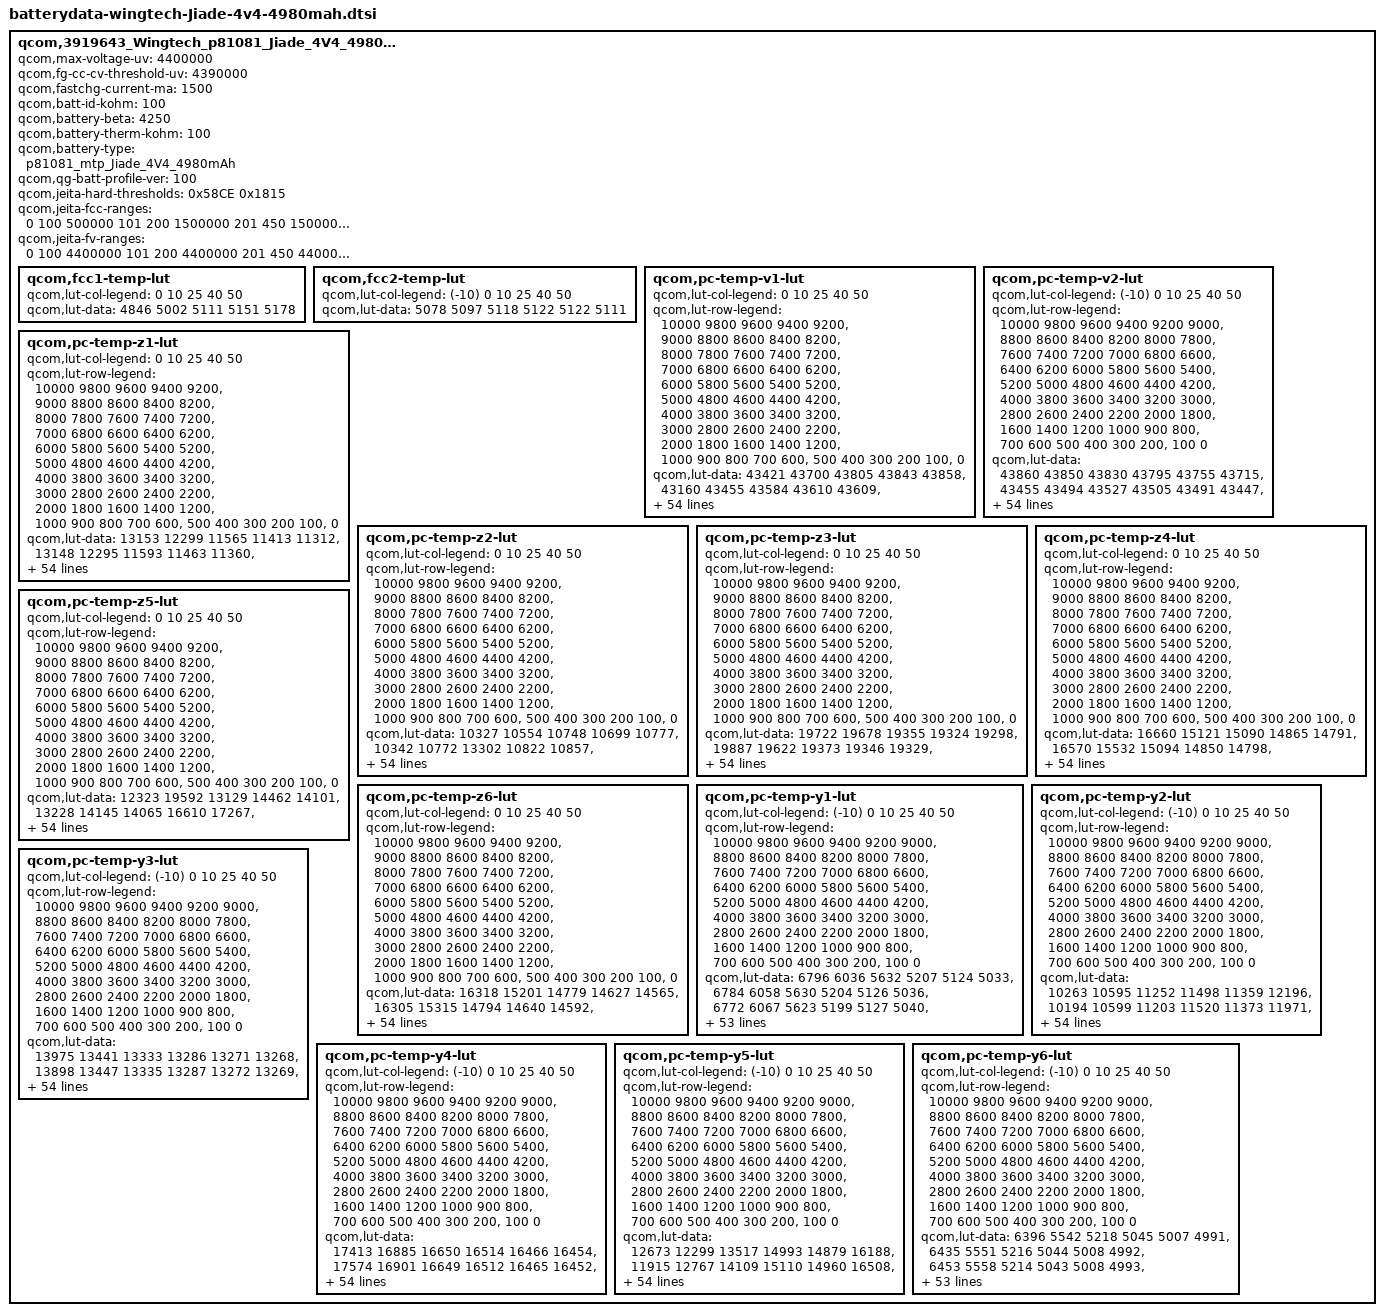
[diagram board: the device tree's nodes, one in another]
qcom,3919643_Wingtech_p81081_Jiade_4V4_4980mAh {
    /* 3919643_Wingtech_p81081_Jiade_4V4_4980mAh_averaged_MasterSlave_Mar12th2019 */
    qcom,max-voltage-uv = <4400000>;
    qcom,fg-cc-cv-threshold-uv = <4390000>;
    qcom,fastchg-current-ma = <1500>;
    qcom,batt-id-kohm = <100>;
    qcom,battery-beta = <4250>;
    qcom,battery-therm-kohm = <100>;
    qcom,battery-type = "p81081_mtp_Jiade_4V4_4980mAh";
    qcom,qg-batt-profile-ver = <100>;

	/*bug 432160 caijiaqi.wt 20190314 0-55 degree C charging, other temperatur don't charging*/
	/* COLD = 0 DegC, HOT = 55 DegC */
	qcom,jeita-hard-thresholds = <0x58CE 0x1815>;
	qcom,jeita-fcc-ranges = <0   100  500000
                                101  200  1500000
                                201  450  1500000
                                451  550  800000>;
        qcom,jeita-fv-ranges = <0   100  4400000
                                101 200  4400000
                                201 450  4400000
                                451 550  4100000>;
	/*bug 432160 caijiaqi.wt 20190314 0-55 degree C charging, other temperatur don't charging*/

	qcom,fcc1-temp-lut {
		qcom,lut-col-legend = <0 10 25 40 50>;
		qcom,lut-data = <4846 5002 5111 5151 5178>;
	};

	qcom,fcc2-temp-lut {
		qcom,lut-col-legend = <(-10) 0 10 25 40 50>;
		qcom,lut-data = <5078 5097 5118 5122 5122 5111>;
	};

	qcom,pc-temp-v1-lut {
		qcom,lut-col-legend = <0 10 25 40 50>;
		qcom,lut-row-legend = <10000 9800 9600 9400 9200>,
			<9000 8800 8600 8400 8200>,
			<8000 7800 7600 7400 7200>,
			<7000 6800 6600 6400 6200>,
			<6000 5800 5600 5400 5200>,
			<5000 4800 4600 4400 4200>,
			<4000 3800 3600 3400 3200>,
			<3000 2800 2600 2400 2200>,
			<2000 1800 1600 1400 1200>,
			<1000 900 800 700 600>,
			<500 400 300 200 100>,
			<0>;
		qcom,lut-data = <43421 43700 43805 43843 43858>,
			<43160 43455 43584 43610 43609>,
			<42917 43201 43344 43383 43387>,
			<42684 42955 43097 43156 43157>,
			<42456 42717 42853 42927 42924>,
			<42231 42484 42614 42691 42692>,
			<42009 42253 42379 42453 42459>,
			<41793 42026 42147 42217 42228>,
			<41580 41804 41919 41986 41998>,
			<41379 41585 41693 41757 41769>,
			<41201 41373 41469 41531 41542>,
			<41026 41181 41253 41311 41319>,
			<40816 41000 41053 41099 41101>,
			<40560 40797 40861 40898 40893>,
			<40320 40553 40654 40694 40688>,
			<40125 40319 40433 40484 40484>,
			<39954 40135 40228 40282 40287>,
			<39805 39975 40051 40103 40107>,
			<39679 39827 39888 39938 39939>,
			<39562 39696 39736 39777 39775>,
			<39444 39561 39598 39626 39618>,
			<39329 39404 39425 39457 39451>,
			<39213 39233 39158 39215 39234>,
			<39096 39050 38903 38959 38993>,
			<38980 38835 38759 38804 38822>,
			<38860 38661 38655 38700 38702>,
			<38738 38568 38570 38603 38595>,
			<38630 38502 38499 38500 38491>,
			<38536 38446 38433 38405 38395>,
			<38455 38400 38363 38321 38306>,
			<38398 38357 38297 38247 38226>,
			<38354 38313 38237 38179 38154>,
			<38316 38269 38184 38121 38091>,
			<38281 38229 38135 38066 38033>,
			<38249 38193 38093 38018 37982>,
			<38215 38156 38054 37973 37934>,
			<38184 38122 38013 37925 37877>,
			<38146 38085 37974 37875 37811>,
			<38087 38030 37921 37813 37736>,
			<38004 37935 37832 37728 37653>,
			<37905 37825 37721 37625 37559>,
			<37784 37710 37606 37513 37448>,
			<37645 37579 37477 37385 37316>,
			<37485 37417 37318 37229 37164>,
			<37341 37272 37172 37084 37021>,
			<37249 37174 37081 36996 36934>,
			<37224 37145 37060 36973 36913>,
			<37192 37127 37040 36960 36898>,
			<37168 37105 37023 36943 36878>,
			<37118 37063 36977 36884 36810>,
			<36875 36829 36730 36620 36534>,
			<36429 36391 36299 36186 36094>,
			<35854 35818 35729 35614 35524>,
			<35070 35035 34950 34832 34742>,
			<33843 33816 33743 33626 33536>,
			<30000 30000 30000 30000 30000>;
	};

	qcom,pc-temp-v2-lut {
		qcom,lut-col-legend = <(-10) 0 10 25 40 50>;
		qcom,lut-row-legend = <10000 9800 9600 9400 9200 9000>,
			<8800 8600 8400 8200 8000 7800>,
			<7600 7400 7200 7000 6800 6600>,
			<6400 6200 6000 5800 5600 5400>,
			<5200 5000 4800 4600 4400 4200>,
			<4000 3800 3600 3400 3200 3000>,
			<2800 2600 2400 2200 2000 1800>,
			<1600 1400 1200 1000 900 800>,
			<700 600 500 400 300 200>,
			<100 0>;
		qcom,lut-data = <43860 43850 43830 43795 43755 43715>,
			<43455 43494 43527 43505 43491 43447>,
			<43091 43172 43244 43233 43236 43189>,
			<42772 42887 42983 42979 42992 42943>,
			<42488 42636 42742 42744 42758 42709>,
			<42239 42393 42505 42511 42525 42477>,
			<42031 42153 42268 42276 42291 42244>,
			<41832 41918 42035 42044 42058 42012>,
			<41580 41684 41807 41815 41830 41784>,
			<41284 41451 41584 41589 41606 41559>,
			<41088 41238 41367 41366 41383 41337>,
			<41004 41057 41155 41146 41163 41120>,
			<40916 40877 40948 40931 40948 40907>,
			<40612 40673 40753 40730 40745 40705>,
			<40037 40449 40561 40535 40548 40507>,
			<39670 40198 40352 40335 40350 40315>,
			<39492 39892 40120 40125 40146 40126>,
			<39342 39616 39889 39930 39955 39944>,
			<39172 39434 39675 39772 39796 39779>,
			<39001 39285 39468 39621 39643 39617>,
			<38830 39122 39267 39427 39452 39426>,
			<38649 38949 39070 39182 39221 39199>,
			<38495 38787 38896 38965 39010 38991>,
			<38384 38642 38745 38790 38831 38814>,
			<38293 38507 38611 38639 38673 38659>,
			<38215 38373 38490 38515 38545 38532>,
			<38150 38238 38380 38409 38437 38425>,
			<38089 38131 38280 38313 38339 38328>,
			<38030 38051 38189 38224 38248 38237>,
			<37975 37986 38103 38141 38165 38154>,
			<37923 37934 38016 38062 38091 38079>,
			<37875 37891 37933 37987 38021 38009>,
			<37825 37849 37870 37920 37956 37944>,
			<37773 37809 37821 37859 37897 37887>,
			<37720 37769 37778 37803 37834 37823>,
			<37663 37724 37740 37749 37752 37727>,
			<37603 37676 37702 37694 37662 37609>,
			<37541 37623 37657 37631 37573 37506>,
			<37474 37565 37604 37556 37483 37414>,
			<37405 37498 37541 37479 37398 37328>,
			<37334 37414 37459 37401 37328 37254>,
			<37260 37313 37361 37312 37245 37173>,
			<37182 37200 37247 37198 37128 37057>,
			<37101 37080 37108 37068 37005 36926>,
			<37012 36951 36956 36923 36871 36801>,
			<36906 36849 36882 36881 36829 36772>,
			<36853 36802 36855 36862 36819 36760>,
			<36780 36753 36833 36838 36799 36742>,
			<36705 36693 36794 36806 36769 36707>,
			<36599 36596 36723 36719 36680 36596>,
			<36381 36396 36484 36436 36391 36279>,
			<36036 36001 36023 35950 35913 35782>,
			<35490 35426 35393 35301 35272 35137>,
			<34685 34614 34536 34405 34384 34232>,
			<33357 33283 33183 32985 33046 32943>,
			<29091 28256 28322 28393 28647 28845>;
	};

	qcom,pc-temp-z1-lut {
		qcom,lut-col-legend = <0 10 25 40 50>;
		qcom,lut-row-legend = <10000 9800 9600 9400 9200>,
			<9000 8800 8600 8400 8200>,
			<8000 7800 7600 7400 7200>,
			<7000 6800 6600 6400 6200>,
			<6000 5800 5600 5400 5200>,
			<5000 4800 4600 4400 4200>,
			<4000 3800 3600 3400 3200>,
			<3000 2800 2600 2400 2200>,
			<2000 1800 1600 1400 1200>,
			<1000 900 800 700 600>,
			<500 400 300 200 100>,
			<0>;
		qcom,lut-data = <13153 12299 11565 11413 11312>,
			<13148 12295 11593 11463 11360>,
			<13167 12314 11586 11470 11354>,
			<13198 12323 11580 11473 11359>,
			<13209 12319 11574 11476 11366>,
			<13180 12311 11570 11476 11367>,
			<13147 12308 11566 11474 11360>,
			<13149 12305 11561 11471 11357>,
			<13171 12305 11553 11466 11361>,
			<13189 12310 11551 11460 11364>,
			<13196 12311 11553 11455 11362>,
			<13200 12299 11554 11451 11358>,
			<13201 12276 11553 11451 11356>,
			<13206 12268 11551 11453 11351>,
			<13204 12267 11548 11455 11348>,
			<13181 12267 11546 11459 11354>,
			<13145 12269 11543 11463 11362>,
			<13125 12272 11541 11465 11363>,
			<13117 12273 11540 11467 11360>,
			<13114 12268 11543 11468 11359>,
			<13106 12264 11552 11463 11359>,
			<13089 12274 11557 11460 11360>,
			<13087 12294 11557 11466 11362>,
			<13106 12298 11556 11474 11366>,
			<13124 12284 11557 11474 11369>,
			<13124 12274 11562 11468 11376>,
			<13117 12282 11564 11465 11380>,
			<13114 12300 11566 11472 11376>,
			<13119 12306 11569 11481 11370>,
			<13127 12302 11575 11482 11370>,
			<13135 12299 11581 11481 11375>,
			<13151 12304 11582 11482 11377>,
			<13161 12313 11579 11486 11381>,
			<13159 12320 11577 11490 11385>,
			<13155 12326 11581 11495 11384>,
			<13151 12331 11590 11500 11383>,
			<13136 12342 11594 11503 11383>,
			<13125 12356 11597 11505 11385>,
			<13144 12358 11600 11505 11387>,
			<13189 12346 11609 11507 11389>,
			<13205 12338 11617 11509 11391>,
			<13199 12351 11618 11509 11392>,
			<13185 12367 11618 11511 11396>,
			<13138 12366 11628 11516 11401>,
			<13130 12348 11637 11519 11403>,
			<13106 12373 11630 11514 11398>,
			<13114 12348 11633 11515 11397>,
			<13108 12337 11644 11515 11393>,
			<13103 12342 11643 11519 11398>,
			<13046 12346 11647 11516 11395>,
			<13107 12358 11648 11516 11405>,
			<13105 12368 11655 11533 11411>,
			<13164 12389 11669 11537 11409>,
			<13121 12415 11684 11543 11418>,
			<13121 12415 11684 11543 11418>,
			<13121 12415 11684 11543 11418>;
	};

	qcom,pc-temp-z2-lut {
		qcom,lut-col-legend = <0 10 25 40 50>;
		qcom,lut-row-legend = <10000 9800 9600 9400 9200>,
			<9000 8800 8600 8400 8200>,
			<8000 7800 7600 7400 7200>,
			<7000 6800 6600 6400 6200>,
			<6000 5800 5600 5400 5200>,
			<5000 4800 4600 4400 4200>,
			<4000 3800 3600 3400 3200>,
			<3000 2800 2600 2400 2200>,
			<2000 1800 1600 1400 1200>,
			<1000 900 800 700 600>,
			<500 400 300 200 100>,
			<0>;
		qcom,lut-data = <10327 10554 10748 10699 10777>,
			<10342 10772 13302 10822 10857>,
			<10363 10562 11865 11106 10915>,
			<10395 10464 11024 11531 11055>,
			<10429 10437 10784 11833 11179>,
			<10473 10421 10744 11575 11170>,
			<10508 10403 10714 11082 11102>,
			<10504 10380 10709 11030 11060>,
			<10477 10370 10716 11353 11046>,
			<10462 10372 10726 11555 11031>,
			<10472 10380 10745 11538 10979>,
			<10487 10398 10773 11509 10898>,
			<10474 10427 10875 11496 10857>,
			<10394 10442 11009 11462 10828>,
			<10336 10447 11030 11439 10805>,
			<10370 10453 11019 11394 10778>,
			<10440 10496 11006 11323 10754>,
			<10482 10575 10927 11166 10776>,
			<10509 10606 10836 10935 10861>,
			<10526 10606 10830 10889 10912>,
			<10522 10601 10839 10909 10939>,
			<10499 10597 10845 10925 10956>,
			<10476 10593 10853 10913 10940>,
			<10420 10593 10860 10895 10906>,
			<10365 10596 10848 10927 10915>,
			<10355 10599 10817 11016 11032>,
			<10353 10597 10814 11075 11122>,
			<10353 10594 10887 11125 11083>,
			<10353 10593 10953 11167 11011>,
			<10354 10594 10956 11129 10986>,
			<10353 10596 10943 11020 10927>,
			<10352 10603 10928 10981 10893>,
			<10351 10615 10898 10993 10897>,
			<10357 10622 10881 11015 10906>,
			<10369 10629 10898 11060 10903>,
			<10384 10634 10927 11134 10903>,
			<10404 10639 10943 11188 10955>,
			<10423 10647 10957 11233 11174>,
			<10436 10660 10974 11262 11315>,
			<10451 10688 11010 11288 11251>,
			<10468 10710 11045 11304 11153>,
			<10506 10714 11048 11239 11138>,
			<10556 10719 11035 11095 11150>,
			<10635 10747 11042 11210 11072>,
			<11069 10972 11101 11336 11017>,
			<11121 11123 11098 11153 11138>,
			<10926 11143 11213 11145 11114>,
			<11276 11390 11201 11111 11032>,
			<10954 11447 11119 11057 11079>,
			<10782 11596 11171 11285 11179>,
			<10894 11133 11524 11335 11156>,
			<10495 11388 11447 11381 11048>,
			<10179 11053 11237 11336 11023>,
			<10124 10641 11343 11292 10902>,
			<10124 10641 11343 11292 10902>,
			<10124 10641 11343 11292 10902>;
	};

	qcom,pc-temp-z3-lut {
		qcom,lut-col-legend = <0 10 25 40 50>;
		qcom,lut-row-legend = <10000 9800 9600 9400 9200>,
			<9000 8800 8600 8400 8200>,
			<8000 7800 7600 7400 7200>,
			<7000 6800 6600 6400 6200>,
			<6000 5800 5600 5400 5200>,
			<5000 4800 4600 4400 4200>,
			<4000 3800 3600 3400 3200>,
			<3000 2800 2600 2400 2200>,
			<2000 1800 1600 1400 1200>,
			<1000 900 800 700 600>,
			<500 400 300 200 100>,
			<0>;
		qcom,lut-data = <19722 19678 19355 19324 19298>,
			<19887 19622 19373 19346 19329>,
			<19894 19663 19432 19379 19349>,
			<19885 19682 19474 19391 19365>,
			<19871 19692 19489 19396 19375>,
			<19833 19698 19492 19396 19377>,
			<19794 19698 19493 19395 19377>,
			<19782 19695 19490 19396 19376>,
			<19776 19692 19480 19401 19367>,
			<19770 19680 19470 19404 19358>,
			<19759 19664 19457 19397 19353>,
			<19746 19649 19449 19387 19350>,
			<19755 19634 19449 19381 19345>,
			<19813 19629 19454 19374 19337>,
			<19853 19630 19456 19372 19333>,
			<19824 19631 19461 19370 19332>,
			<19765 19628 19464 19366 19332>,
			<19732 19620 19445 19359 19330>,
			<19712 19611 19420 19347 19324>,
			<19701 19585 19416 19344 19322>,
			<19714 19565 19418 19342 19324>,
			<19751 19578 19423 19341 19325>,
			<19787 19610 19440 19345 19323>,
			<19839 19627 19455 19351 19319>,
			<19890 19637 19450 19350 19319>,
			<19913 19642 19436 19340 19324>,
			<19928 19639 19428 19336 19330>,
			<19933 19633 19422 19356 19342>,
			<19929 19626 19418 19380 19357>,
			<19922 19616 19428 19381 19358>,
			<19913 19608 19448 19380 19356>,
			<19897 19605 19453 19378 19354>,
			<19880 19602 19452 19374 19350>,
			<19865 19600 19450 19370 19345>,
			<19850 19597 19445 19365 19338>,
			<19831 19594 19438 19361 19331>,
			<19807 19587 19433 19357 19330>,
			<19787 19578 19428 19355 19332>,
			<19778 19574 19424 19353 19334>,
			<19771 19572 19419 19351 19331>,
			<19760 19568 19415 19349 19327>,
			<19726 19557 19410 19346 19325>,
			<19689 19539 19406 19340 19325>,
			<19647 19524 19403 19340 19323>,
			<19528 19472 19394 19338 19320>,
			<19448 19428 19373 19327 19317>,
			<19374 19421 19356 19326 19312>,
			<19398 19379 19358 19314 19306>,
			<19362 19367 19348 19311 19306>,
			<19336 19342 19332 19308 19299>,
			<19362 19325 19330 19317 19307>,
			<19343 19337 19311 19297 19311>,
			<19351 19326 19304 19304 19301>,
			<19360 19320 19298 19304 19299>,
			<19360 19320 19298 19304 19299>,
			<19360 19320 19298 19304 19299>;
	};

	qcom,pc-temp-z4-lut {
		qcom,lut-col-legend = <0 10 25 40 50>;
		qcom,lut-row-legend = <10000 9800 9600 9400 9200>,
			<9000 8800 8600 8400 8200>,
			<8000 7800 7600 7400 7200>,
			<7000 6800 6600 6400 6200>,
			<6000 5800 5600 5400 5200>,
			<5000 4800 4600 4400 4200>,
			<4000 3800 3600 3400 3200>,
			<3000 2800 2600 2400 2200>,
			<2000 1800 1600 1400 1200>,
			<1000 900 800 700 600>,
			<500 400 300 200 100>,
			<0>;
		qcom,lut-data = <16660 15121 15090 14865 14791>,
			<16570 15532 15094 14850 14798>,
			<16432 15462 15134 14903 14838>,
			<16249 15389 15047 14863 14820>,
			<16084 15279 14975 14820 14790>,
			<15939 15165 14927 14802 14768>,
			<15813 15090 14886 14788 14750>,
			<15726 15029 14850 14768 14737>,
			<15659 14986 14819 14733 14729>,
			<15596 14957 14802 14711 14722>,
			<15528 14931 14794 14706 14716>,
			<15465 14897 14786 14703 14711>,
			<15414 14863 14766 14699 14706>,
			<15368 14853 14743 14691 14702>,
			<15340 14856 14729 14687 14698>,
			<15332 14859 14719 14683 14691>,
			<15327 14844 14712 14679 14683>,
			<15317 14810 14715 14676 14676>,
			<15291 14795 14721 14676 14669>,
			<15252 14794 14718 14678 14666>,
			<15189 14794 14708 14678 14665>,
			<15095 14789 14707 14680 14665>,
			<15017 14779 14773 14733 14704>,
			<14942 14784 14845 14813 14786>,
			<14885 14845 14859 14824 14804>,
			<14871 14896 14865 14818 14790>,
			<14866 14893 14865 14809 14771>,
			<14867 14884 14852 14774 14745>,
			<14875 14873 14831 14733 14715>,
			<14884 14860 14802 14715 14699>,
			<14885 14845 14768 14704 14689>,
			<14883 14830 14749 14696 14681>,
			<14880 14816 14736 14688 14675>,
			<14875 14803 14728 14684 14671>,
			<14869 14792 14724 14684 14672>,
			<14867 14784 14721 14685 14675>,
			<14868 14779 14721 14687 14680>,
			<14868 14775 14721 14693 14688>,
			<14861 14775 14722 14699 14695>,
			<14846 14776 14732 14705 14698>,
			<14841 14777 14742 14710 14699>,
			<14857 14777 14739 14709 14697>,
			<14867 14777 14731 14705 14691>,
			<14864 14776 14729 14704 14693>,
			<14850 14769 14719 14700 14694>,
			<14887 14764 14702 14685 14674>,
			<14963 14765 14706 14674 14667>,
			<14928 14799 14690 14669 14657>,
			<14961 14804 14691 14657 14640>,
			<14977 14827 14707 14665 14652>,
			<14951 14859 14729 14678 14662>,
			<14995 14854 14759 14703 14664>,
			<15004 14871 14769 14695 14675>,
			<15006 14884 14777 14697 14678>,
			<15006 14884 14777 14697 14678>,
			<15006 14884 14777 14697 14678>;
	};

	qcom,pc-temp-z5-lut {
		qcom,lut-col-legend = <0 10 25 40 50>;
		qcom,lut-row-legend = <10000 9800 9600 9400 9200>,
			<9000 8800 8600 8400 8200>,
			<8000 7800 7600 7400 7200>,
			<7000 6800 6600 6400 6200>,
			<6000 5800 5600 5400 5200>,
			<5000 4800 4600 4400 4200>,
			<4000 3800 3600 3400 3200>,
			<3000 2800 2600 2400 2200>,
			<2000 1800 1600 1400 1200>,
			<1000 900 800 700 600>,
			<500 400 300 200 100>,
			<0>;
		qcom,lut-data = <12323 19592 13129 14462 14101>,
			<13228 14145 14065 16610 17267>,
			<13409 14947 15320 17938 18068>,
			<13480 15554 16689 18315 19632>,
			<13562 16010 17534 18656 21140>,
			<13699 16423 17964 18937 21545>,
			<13815 16922 18316 19235 21791>,
			<13844 17435 18764 20149 21829>,
			<13841 17691 19202 22936 21251>,
			<13835 17807 19348 24527 20674>,
			<13824 17917 19192 24096 20597>,
			<13819 18198 19102 23401 20588>,
			<13966 18747 20001 23446 20400>,
			<14662 19360 21625 24723 19752>,
			<15149 20175 22787 25289 19372>,
			<14848 20926 23983 24943 19811>,
			<14254 21293 24755 24319 20535>,
			<13970 21349 23394 23209 20932>,
			<13832 21215 21612 21828 21221>,
			<13759 20561 22310 21885 21703>,
			<14170 20550 24752 22559 23757>,
			<15529 25616 28342 23143 25557>,
			<17320 35587 37469 24127 24267>,
			<20621 40791 45271 25206 21062>,
			<24945 43571 41857 24010 19012>,
			<29845 44973 31741 19150 17419>,
			<35716 42779 25888 16833 16688>,
			<38820 37606 22665 18778 18086>,
			<39372 33756 21082 21680 20662>,
			<39243 30572 22484 23575 22648>,
			<38111 28801 25700 25178 24464>,
			<35059 28721 28294 27044 26229>,
			<32070 28813 31122 29547 28331>,
			<30202 28989 33159 31493 29696>,
			<28608 29698 34281 32696 29540>,
			<26895 30208 34983 33758 29112>,
			<24750 29626 34798 33575 29035>,
			<23420 28577 33615 32062 29268>,
			<23875 28422 32251 30193 29424>,
			<24992 29187 30120 27949 27111>,
			<25234 29711 27907 25583 23577>,
			<22857 27429 26487 23793 22659>,
			<21222 24318 25355 22349 22358>,
			<20173 23297 24578 21760 20993>,
			<18607 21229 24023 21384 19846>,
			<15860 18783 22440 20383 20105>,
			<13502 18169 19312 20851 19617>,
			<14016 15248 20586 18656 19313>,
			<13223 14705 18327 19115 22544>,
			<12805 13801 16469 17912 18456>,
			<13476 13292 15668 17674 16957>,
			<12789 13423 13924 14318 17014>,
			<12633 12961 13355 14627 14866>,
			<12594 12625 13032 14360 14654>,
			<12594 12625 13032 14360 14654>,
			<12594 12625 13032 14360 14654>;
	};

	qcom,pc-temp-z6-lut {
		qcom,lut-col-legend = <0 10 25 40 50>;
		qcom,lut-row-legend = <10000 9800 9600 9400 9200>,
			<9000 8800 8600 8400 8200>,
			<8000 7800 7600 7400 7200>,
			<7000 6800 6600 6400 6200>,
			<6000 5800 5600 5400 5200>,
			<5000 4800 4600 4400 4200>,
			<4000 3800 3600 3400 3200>,
			<3000 2800 2600 2400 2200>,
			<2000 1800 1600 1400 1200>,
			<1000 900 800 700 600>,
			<500 400 300 200 100>,
			<0>;
		qcom,lut-data = <16318 15201 14779 14627 14565>,
			<16305 15315 14794 14640 14592>,
			<16253 15300 14827 14680 14618>,
			<16141 15280 14811 14670 14617>,
			<16031 15230 14796 14658 14614>,
			<15919 15173 14777 14650 14609>,
			<15823 15136 14756 14643 14600>,
			<15773 15105 14736 14634 14591>,
			<15742 15080 14717 14622 14584>,
			<15712 15057 14704 14612 14577>,
			<15665 15035 14694 14604 14571>,
			<15623 15010 14685 14598 14566>,
			<15617 14985 14677 14592 14560>,
			<15623 14976 14669 14587 14554>,
			<15627 14976 14665 14583 14549>,
			<15603 14976 14662 14580 14546>,
			<15554 14968 14659 14578 14544>,
			<15522 14951 14649 14573 14540>,
			<15504 14936 14638 14567 14533>,
			<15488 14921 14636 14564 14531>,
			<15462 14912 14635 14563 14531>,
			<15431 14917 14636 14563 14531>,
			<15422 14930 14674 14588 14548>,
			<15430 14947 14713 14627 14582>,
			<15439 14979 14715 14632 14590>,
			<15442 15001 14713 14624 14588>,
			<15445 15000 14710 14617 14584>,
			<15446 14997 14701 14613 14579>,
			<15446 14992 14691 14610 14572>,
			<15445 14980 14685 14605 14567>,
			<15445 14970 14680 14598 14563>,
			<15442 14963 14675 14593 14559>,
			<15439 14958 14670 14588 14553>,
			<15433 14955 14665 14584 14549>,
			<15424 14952 14660 14582 14545>,
			<15414 14950 14657 14581 14543>,
			<15396 14946 14655 14581 14543>,
			<15382 14943 14653 14582 14548>,
			<15380 14941 14652 14583 14552>,
			<15379 14939 14656 14585 14551>,
			<15376 14939 14660 14586 14551>,
			<15365 14938 14657 14584 14549>,
			<15349 14934 14652 14579 14546>,
			<15322 14929 14651 14580 14547>,
			<15252 14900 14644 14578 14547>,
			<15241 14885 14626 14564 14535>,
			<15234 14879 14620 14560 14530>,
			<15224 14872 14615 14552 14522>,
			<15225 14864 14611 14545 14514>,
			<15213 14866 14612 14546 14515>,
			<15236 14880 14620 14556 14527>,
			<15247 14882 14626 14561 14531>,
			<15280 14895 14631 14562 14531>,
			<15291 14914 14635 14564 14533>,
			<15291 14914 14635 14564 14533>,
			<15291 14914 14635 14564 14533>;
	};

	qcom,pc-temp-y1-lut {
		qcom,lut-col-legend = <(-10) 0 10 25 40 50>;
		qcom,lut-row-legend = <10000 9800 9600 9400 9200 9000>,
			<8800 8600 8400 8200 8000 7800>,
			<7600 7400 7200 7000 6800 6600>,
			<6400 6200 6000 5800 5600 5400>,
			<5200 5000 4800 4600 4400 4200>,
			<4000 3800 3600 3400 3200 3000>,
			<2800 2600 2400 2200 2000 1800>,
			<1600 1400 1200 1000 900 800>,
			<700 600 500 400 300 200>,
			<100 0>;
		qcom,lut-data = <6796 6036 5632 5207 5124 5033>,
			<6784 6058 5630 5204 5126 5036>,
			<6772 6067 5623 5199 5127 5040>,
			<6762 6068 5614 5193 5127 5043>,
			<6754 6065 5606 5188 5127 5045>,
			<6750 6063 5603 5185 5127 5046>,
			<6750 6052 5603 5182 5125 5046>,
			<6750 6039 5602 5179 5123 5046>,
			<6746 6041 5599 5178 5119 5046>,
			<6740 6050 5596 5176 5112 5044>,
			<6739 6054 5594 5174 5110 5043>,
			<6759 6042 5594 5171 5112 5042>,
			<6780 6030 5593 5169 5113 5041>,
			<6777 6035 5587 5169 5113 5042>,
			<6767 6047 5576 5170 5111 5046>,
			<6754 6049 5574 5172 5111 5047>,
			<6732 6033 5579 5174 5113 5043>,
			<6715 6017 5584 5176 5114 5039>,
			<6717 6018 5585 5176 5112 5040>,
			<6724 6025 5585 5175 5110 5042>,
			<6723 6025 5587 5175 5110 5041>,
			<6707 6018 5592 5175 5112 5040>,
			<6695 6015 5597 5176 5114 5039>,
			<6702 6017 5599 5179 5112 5039>,
			<6713 6020 5600 5182 5110 5039>,
			<6713 6020 5598 5184 5112 5042>,
			<6701 6015 5590 5187 5116 5048>,
			<6690 6014 5585 5188 5118 5051>,
			<6688 6019 5586 5191 5121 5050>,
			<6687 6028 5589 5195 5124 5049>,
			<6682 6038 5593 5196 5124 5050>,
			<6673 6053 5600 5200 5125 5052>,
			<6668 6057 5608 5203 5125 5054>,
			<6656 6053 5622 5209 5126 5058>,
			<6644 6046 5631 5215 5127 5061>,
			<6649 6039 5624 5219 5132 5061>,
			<6660 6030 5612 5222 5139 5062>,
			<6668 6028 5612 5223 5141 5065>,
			<6676 6037 5626 5224 5142 5075>,
			<6682 6044 5633 5225 5143 5081>,
			<6700 6042 5626 5230 5142 5076>,
			<6727 6039 5622 5235 5143 5074>,
			<6690 6044 5623 5239 5149 5077>,
			<6668 6047 5632 5241 5149 5074>,
			<6711 6063 5635 5248 5151 5076>,
			<6687 6058 5656 5250 5151 5075>,
			<6656 6065 5655 5254 5153 5072>,
			<6724 6057 5661 5253 5152 5075>,
			<6676 6058 5650 5262 5154 5077>,
			<6686 6043 5662 5263 5152 5075>,
			<6667 6045 5658 5259 5157 5077>,
			<6686 6053 5652 5273 5158 5081>,
			<6757 6074 5663 5286 5156 5083>,
			<6765 6103 5683 5304 5165 5085>,
			<6765 6103 5683 5304 5165 5085>,
			<6765 6103 5683 5304 5165 5085>;
	};

	qcom,pc-temp-y2-lut {
		qcom,lut-col-legend = <(-10) 0 10 25 40 50>;
		qcom,lut-row-legend = <10000 9800 9600 9400 9200 9000>,
			<8800 8600 8400 8200 8000 7800>,
			<7600 7400 7200 7000 6800 6600>,
			<6400 6200 6000 5800 5600 5400>,
			<5200 5000 4800 4600 4400 4200>,
			<4000 3800 3600 3400 3200 3000>,
			<2800 2600 2400 2200 2000 1800>,
			<1600 1400 1200 1000 900 800>,
			<700 600 500 400 300 200>,
			<100 0>;
		qcom,lut-data = <10263 10595 11252 11498 11359 12196>,
			<10194 10599 11203 11520 11373 11971>,
			<10166 10604 11146 11519 11396 11730>,
			<10170 10610 11090 11502 11422 11514>,
			<10196 10616 11046 11480 11441 11363>,
			<10235 10622 11021 11460 11448 11316>,
			<10325 10638 11010 11432 11445 11363>,
			<10425 10654 11005 11398 11444 11428>,
			<10461 10650 11004 11371 11471 11443>,
			<10479 10632 11003 11344 11547 11422>,
			<10503 10633 11003 11339 11577 11415>,
			<10561 10793 11003 11381 11577 11468>,
			<10609 10951 11003 11423 11570 11512>,
			<10413 10947 11034 11418 11515 11468>,
			<9886 10919 11108 11399 11417 11386>,
			<9690 10914 11159 11411 11401 11359>,
			<9680 10948 11196 11488 11467 11399>,
			<9674 10994 11218 11553 11544 11434>,
			<9671 11035 11227 11577 11633 11507>,
			<9668 11080 11234 11592 11717 11628>,
			<9667 11129 11257 11591 11727 11660>,
			<9666 11183 11323 11581 11717 11671>,
			<9666 11233 11384 11576 11713 11679>,
			<9664 11284 11428 11606 11771 11689>,
			<9663 11326 11466 11658 11839 11695>,
			<9662 11344 11501 11720 11836 11680>,
			<9661 11356 11532 11800 11802 11631>,
			<9661 11361 11558 11828 11764 11621>,
			<9660 11375 11581 11812 11710 11718>,
			<9660 11383 11601 11796 11660 11813>,
			<9659 11343 11620 11802 11637 11797>,
			<9659 11241 11638 11817 11633 11750>,
			<9659 11112 11636 11820 11653 11753>,
			<9658 10752 11578 11804 11747 11786>,
			<9658 10409 11534 11791 11835 11826>,
			<9658 10181 11507 11785 11891 11902>,
			<9658 9820 11457 11781 11937 11990>,
			<9658 9705 11419 11788 11912 11984>,
			<9657 9688 11359 11797 11756 11861>,
			<9657 9678 11293 11797 11681 11762>,
			<9657 9672 11229 11679 11815 11671>,
			<9657 9669 11164 11572 11888 11601>,
			<9656 9665 11094 11572 11867 11527>,
			<9656 9663 10976 11581 11928 11443>,
			<9656 9662 10901 11594 11730 11987>,
			<9656 9660 10677 11533 11499 11335>,
			<9656 9659 10589 11458 11568 11526>,
			<9656 9658 10661 11375 11714 11452>,
			<9656 9657 10608 11324 11320 11627>,
			<9655 9657 10560 11135 11318 11484>,
			<9655 9656 10256 11060 11597 11363>,
			<9654 9655 9887 11096 11450 11096>,
			<9652 9655 9708 11049 11338 11064>,
			<9651 9653 9677 10978 11053 10859>,
			<9651 9653 9677 10978 11053 10859>,
			<9651 9653 9677 10978 11053 10859>;
	};

	qcom,pc-temp-y3-lut {
		qcom,lut-col-legend = <(-10) 0 10 25 40 50>;
		qcom,lut-row-legend = <10000 9800 9600 9400 9200 9000>,
			<8800 8600 8400 8200 8000 7800>,
			<7600 7400 7200 7000 6800 6600>,
			<6400 6200 6000 5800 5600 5400>,
			<5200 5000 4800 4600 4400 4200>,
			<4000 3800 3600 3400 3200 3000>,
			<2800 2600 2400 2200 2000 1800>,
			<1600 1400 1200 1000 900 800>,
			<700 600 500 400 300 200>,
			<100 0>;
		qcom,lut-data = <13975 13441 13333 13286 13271 13268>,
			<13898 13447 13335 13287 13272 13269>,
			<13852 13456 13339 13289 13273 13271>,
			<13829 13465 13344 13290 13274 13272>,
			<13821 13472 13347 13292 13274 13272>,
			<13821 13475 13348 13292 13275 13273>,
			<13877 13476 13348 13293 13275 13273>,
			<13947 13476 13348 13293 13275 13274>,
			<13878 13480 13349 13293 13277 13274>,
			<13622 13490 13351 13293 13281 13275>,
			<13512 13492 13352 13293 13282 13275>,
			<13575 13474 13353 13293 13281 13276>,
			<13642 13454 13354 13292 13281 13277>,
			<13624 13452 13357 13294 13281 13278>,
			<13562 13453 13361 13299 13280 13279>,
			<13521 13451 13362 13301 13280 13279>,
			<13496 13441 13361 13302 13281 13277>,
			<13484 13431 13360 13303 13283 13276>,
			<13491 13422 13356 13305 13284 13278>,
			<13506 13413 13350 13307 13286 13280>,
			<13509 13405 13342 13307 13286 13280>,
			<13506 13395 13332 13303 13284 13278>,
			<13504 13386 13325 13298 13282 13276>,
			<13514 13377 13321 13290 13279 13273>,
			<13535 13367 13319 13284 13276 13271>,
			<13558 13357 13319 13284 13275 13270>,
			<13585 13346 13318 13286 13274 13270>,
			<13615 13338 13318 13287 13274 13270>,
			<13651 13330 13318 13288 13274 13271>,
			<13690 13322 13318 13289 13275 13271>,
			<13727 13322 13314 13288 13275 13271>,
			<13766 13327 13307 13286 13275 13271>,
			<13804 13332 13305 13286 13276 13271>,
			<13840 13341 13307 13288 13276 13273>,
			<13878 13350 13308 13290 13277 13274>,
			<13925 13357 13311 13291 13278 13273>,
			<13982 13365 13316 13292 13279 13271>,
			<14045 13376 13319 13291 13278 13270>,
			<14118 13396 13322 13287 13276 13270>,
			<14192 13420 13324 13284 13274 13269>,
			<14257 13443 13325 13282 13273 13270>,
			<14316 13474 13325 13281 13273 13271>,
			<14373 13527 13329 13287 13276 13271>,
			<14414 13603 13327 13290 13278 13269>,
			<14307 13582 13314 13286 13278 13273>,
			<14432 13699 13325 13290 13274 13272>,
			<14500 13781 13329 13289 13278 13274>,
			<14563 13866 13344 13287 13277 13278>,
			<14691 13995 13354 13295 13280 13279>,
			<14814 14105 13371 13302 13280 13278>,
			<14927 14221 13373 13297 13282 13275>,
			<15171 14370 13382 13303 13283 13274>,
			<15825 14642 13434 13311 13278 13276>,
			<16759 15023 13537 13322 13282 13279>,
			<16759 15023 13537 13322 13282 13279>,
			<16759 15023 13537 13322 13282 13279>;
	};

	qcom,pc-temp-y4-lut {
		qcom,lut-col-legend = <(-10) 0 10 25 40 50>;
		qcom,lut-row-legend = <10000 9800 9600 9400 9200 9000>,
			<8800 8600 8400 8200 8000 7800>,
			<7600 7400 7200 7000 6800 6600>,
			<6400 6200 6000 5800 5600 5400>,
			<5200 5000 4800 4600 4400 4200>,
			<4000 3800 3600 3400 3200 3000>,
			<2800 2600 2400 2200 2000 1800>,
			<1600 1400 1200 1000 900 800>,
			<700 600 500 400 300 200>,
			<100 0>;
		qcom,lut-data = <17413 16885 16650 16514 16466 16454>,
			<17574 16901 16649 16512 16465 16452>,
			<17671 16919 16648 16510 16465 16450>,
			<17719 16936 16648 16509 16465 16449>,
			<17736 16950 16648 16509 16465 16449>,
			<17737 16958 16648 16509 16466 16449>,
			<17578 16964 16649 16513 16469 16450>,
			<17380 16967 16652 16518 16472 16452>,
			<17493 16959 16659 16525 16472 16454>,
			<17945 16933 16672 16532 16471 16458>,
			<18142 16928 16683 16541 16472 16461>,
			<18094 17042 16690 16551 16478 16464>,
			<18002 17159 16699 16562 16488 16468>,
			<17819 17169 16738 16573 16497 16472>,
			<17524 17156 16800 16585 16508 16478>,
			<17411 17115 16814 16598 16517 16485>,
			<17399 16950 16803 16613 16525 16495>,
			<17387 16825 16785 16630 16535 16505>,
			<17335 16826 16742 16654 16555 16519>,
			<17237 16829 16682 16676 16577 16533>,
			<17151 16825 16644 16662 16573 16531>,
			<17066 16798 16615 16585 16541 16511>,
			<17013 16770 16598 16532 16509 16490>,
			<16998 16755 16590 16513 16482 16470>,
			<16989 16741 16584 16501 16462 16455>,
			<16984 16718 16581 16499 16462 16454>,
			<16980 16681 16579 16498 16464 16455>,
			<16978 16665 16577 16498 16467 16457>,
			<16981 16675 16578 16503 16471 16461>,
			<16984 16689 16578 16509 16478 16468>,
			<16986 16696 16576 16516 16486 16475>,
			<16986 16701 16573 16524 16496 16484>,
			<16986 16709 16573 16528 16505 16493>,
			<16988 16726 16577 16530 16514 16502>,
			<16992 16744 16583 16530 16519 16508>,
			<16995 16764 16589 16527 16506 16495>,
			<17000 16792 16598 16521 16482 16469>,
			<17005 16808 16607 16515 16471 16459>,
			<17011 16817 16618 16509 16464 16455>,
			<17017 16823 16626 16506 16462 16454>,
			<17027 16826 16631 16518 16470 16459>,
			<17042 16825 16633 16528 16475 16462>,
			<17061 16821 16635 16524 16468 16460>,
			<17071 16810 16638 16524 16469 16461>,
			<17015 16786 16624 16503 16454 16440>,
			<17016 16798 16638 16513 16469 16458>,
			<17023 16823 16660 16532 16475 16464>,
			<17054 16860 16672 16560 16488 16472>,
			<17078 16912 16711 16580 16507 16489>,
			<17095 16977 16760 16598 16513 16488>,
			<17102 17018 16771 16571 16477 16463>,
			<17086 17025 16781 16562 16471 16463>,
			<17270 17035 16814 16577 16486 16468>,
			<17633 17127 16874 16617 16497 16481>,
			<17633 17127 16874 16617 16497 16481>,
			<17633 17127 16874 16617 16497 16481>;
	};

	qcom,pc-temp-y5-lut {
		qcom,lut-col-legend = <(-10) 0 10 25 40 50>;
		qcom,lut-row-legend = <10000 9800 9600 9400 9200 9000>,
			<8800 8600 8400 8200 8000 7800>,
			<7600 7400 7200 7000 6800 6600>,
			<6400 6200 6000 5800 5600 5400>,
			<5200 5000 4800 4600 4400 4200>,
			<4000 3800 3600 3400 3200 3000>,
			<2800 2600 2400 2200 2000 1800>,
			<1600 1400 1200 1000 900 800>,
			<700 600 500 400 300 200>,
			<100 0>;
		qcom,lut-data = <12673 12299 13517 14993 14879 16188>,
			<11915 12767 14109 15110 14960 16508>,
			<11578 13304 14613 15180 14995 16715>,
			<11590 13828 15002 15215 14993 16831>,
			<11880 14257 15245 15227 14963 16880>,
			<12404 14510 15313 15224 14910 16884>,
			<15098 14616 15131 14992 14679 16719>,
			<18133 14706 14875 14621 14444 16429>,
			<17244 14977 14705 14316 14821 16103>,
			<13164 15492 14511 13994 15938 15703>,
			<11500 15629 14437 13690 16309 15455>,
			<14789 14601 14380 13339 15763 15555>,
			<18261 13591 14344 13121 15030 15727>,
			<17078 14928 14413 13153 14380 15719>,
			<13397 18183 14592 13263 13773 15587>,
			<12108 19104 15124 13417 13659 15242>,
			<12167 18311 17260 13715 13800 14521>,
			<12272 17598 18884 14177 14019 14069>,
			<12562 17466 19181 15174 14325 14264>,
			<13013 17360 19344 16660 14821 14739>,
			<13075 17248 18988 18233 15940 15540>,
			<12607 17134 17274 20095 18372 17296>,
			<12132 17067 16188 20818 19616 18184>,
			<11873 17001 15928 18295 19252 17722>,
			<11680 16887 15778 15352 18554 17020>,
			<11653 16529 15849 15273 17891 16605>,
			<11675 15464 16149 15847 16997 16257>,
			<11689 14838 16445 16369 16449 16059>,
			<11676 13877 16929 16980 16292 16089>,
			<11657 12848 17296 17396 16400 16186>,
			<11684 12831 16744 17161 16682 16174>,
			<11808 13045 15465 16645 17037 16145>,
			<11899 13238 14975 16674 17463 16325>,
			<11952 13363 14957 17934 17999 17313>,
			<11983 13411 15084 19243 18695 18282>,
			<11970 13227 15498 20103 20318 18500>,
			<11943 12859 16041 20744 22137 18444>,
			<11914 12817 16213 20346 21820 18340>,
			<11882 12987 16268 18088 19298 17471>,
			<11850 13102 16319 16289 17808 16814>,
			<11795 12957 16049 15144 16754 16578>,
			<11726 12760 15817 14487 16280 16471>,
			<11704 12668 15906 16001 16836 15765>,
			<11753 12745 15146 16014 18442 15342>,
			<11805 12235 13454 15727 21403 19056>,
			<11924 12505 13905 16062 15536 15906>,
			<12149 12480 13805 14675 16182 16524>,
			<11893 12534 14634 13541 14927 17049>,
			<12150 12753 14770 14214 15395 16961>,
			<12508 12971 15413 14927 15087 16263>,
			<12117 13095 14307 14744 17149 15642>,
			<12170 12816 13125 15469 19509 15100>,
			<11130 12638 12749 16030 15572 15393>,
			<10516 12051 12862 17087 15828 17513>,
			<10516 12051 12862 17087 15828 17513>,
			<10516 12051 12862 17087 15828 17513>;
	};

	qcom,pc-temp-y6-lut {
		qcom,lut-col-legend = <(-10) 0 10 25 40 50>;
		qcom,lut-row-legend = <10000 9800 9600 9400 9200 9000>,
			<8800 8600 8400 8200 8000 7800>,
			<7600 7400 7200 7000 6800 6600>,
			<6400 6200 6000 5800 5600 5400>,
			<5200 5000 4800 4600 4400 4200>,
			<4000 3800 3600 3400 3200 3000>,
			<2800 2600 2400 2200 2000 1800>,
			<1600 1400 1200 1000 900 800>,
			<700 600 500 400 300 200>,
			<100 0>;
		qcom,lut-data = <6396 5542 5218 5045 5007 4991>,
			<6435 5551 5216 5044 5008 4992>,
			<6453 5558 5214 5043 5008 4993>,
			<6455 5562 5213 5043 5008 4993>,
			<6452 5564 5211 5043 5009 4994>,
			<6449 5564 5210 5043 5009 4995>,
			<6439 5559 5207 5044 5010 4996>,
			<6422 5553 5205 5046 5011 4996>,
			<6403 5548 5206 5047 5012 4997>,
			<6374 5543 5209 5049 5013 4998>,
			<6363 5543 5211 5051 5015 5000>,
			<6394 5554 5212 5054 5017 5001>,
			<6426 5566 5215 5056 5019 5003>,
			<6368 5568 5224 5061 5021 5005>,
			<6208 5568 5241 5066 5024 5008>,
			<6143 5559 5244 5072 5027 5010>,
			<6135 5506 5241 5078 5030 5012>,
			<6130 5461 5235 5083 5033 5014>,
			<6126 5455 5221 5091 5041 5018>,
			<6123 5452 5200 5098 5048 5024>,
			<6117 5447 5183 5094 5047 5024>,
			<6100 5435 5168 5070 5036 5016>,
			<6089 5427 5159 5050 5025 5008>,
			<6105 5422 5154 5039 5014 5000>,
			<6136 5418 5152 5033 5007 4994>,
			<6157 5414 5152 5033 5006 4994>,
			<6174 5407 5153 5033 5006 4994>,
			<6195 5405 5155 5035 5007 4995>,
			<6227 5410 5157 5037 5009 4996>,
			<6265 5421 5158 5040 5011 4998>,
			<6294 5435 5158 5042 5014 5000>,
			<6323 5459 5157 5044 5017 5003>,
			<6350 5484 5158 5046 5020 5006>,
			<6375 5510 5165 5049 5023 5010>,
			<6402 5539 5173 5051 5024 5013>,
			<6437 5569 5180 5051 5022 5008>,
			<6482 5601 5188 5051 5017 4999>,
			<6532 5637 5198 5050 5013 4996>,
			<6590 5680 5213 5045 5010 4995>,
			<6649 5726 5226 5043 5008 4995>,
			<6706 5771 5236 5046 5010 4997>,
			<6761 5820 5246 5050 5011 4999>,
			<6808 5882 5262 5053 5012 4999>,
			<6836 5955 5280 5056 5013 4998>,
			<6746 5935 5266 5048 5010 4993>,
			<6847 6042 5302 5055 5012 4999>,
			<6892 6116 5325 5061 5016 5002>,
			<6956 6202 5364 5068 5019 5007>,
			<7062 6316 5399 5081 5027 5013>,
			<7161 6420 5448 5092 5029 5012>,
			<7247 6528 5476 5083 5020 5003>,
			<7451 6643 5516 5088 5019 5003>,
			<8066 6858 5618 5104 5021 5006>,
			<8918 7207 5771 5132 5028 5013>,
			<8918 7207 5771 5132 5028 5013>,
			<8918 7207 5771 5132 5028 5013>;
	};

};
